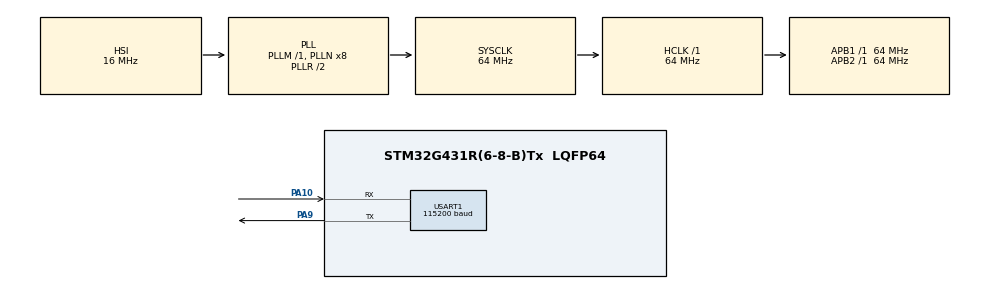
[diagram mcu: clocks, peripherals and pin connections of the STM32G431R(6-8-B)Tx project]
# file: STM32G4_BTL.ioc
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CRC.InputDataFormat=CRC_INPUTDATA_FORMAT_WORDS
Mcu.Family=STM32G4
Mcu.Name=STM32G431R(6-8-B)Tx
Mcu.Package=LQFP64
NVIC.PriorityGroup=NVIC_PRIORITYGROUP_4
PA10.Mode=Asynchronous
PA10.Signal=USART1_RX
PA9.Mode=Asynchronous
PA9.Signal=USART1_TX
ProjectManager.HeapSize=0x200
ProjectManager.StackSize=0x400
ProjectManager.TargetToolchain=STM32CubeIDE
RCC.ADC12Freq_Value=64000000
RCC.AHBFreq_Value=64000000
RCC.APB1Freq_Value=64000000
RCC.APB1TimFreq_Value=64000000
RCC.APB2Freq_Value=64000000
RCC.APB2TimFreq_Value=64000000
RCC.CortexFreq_Value=64000000
RCC.EXTERNAL_CLOCK_VALUE=12288000
RCC.HCLKFreq_Value=64000000
RCC.HSE_VALUE=8000000
RCC.HSI48_VALUE=48000000
RCC.HSI_VALUE=16000000
RCC.LSE_VALUE=32768
RCC.SYSCLKFreq_VALUE=64000000
RCC.SYSCLKSource=RCC_SYSCLKSOURCE_PLLCLK
RCC.USBFreq_Value=64000000
RCC.VCOOutputFreq_Value=128000000
USART1.BaudRate=115200
USART1.VirtualMode-Asynchronous=VM_ASYNC
VP_CRC_VS_CRC.Mode=CRC_Activate
VP_SYS_VS_DBSignals.Mode=DisableDeadBatterySignals
board=custom

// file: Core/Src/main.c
/* USER CODE BEGIN Header */
/**
  ******************************************************************************
  * @file           : main.c
  * @brief          : Main program body
  ******************************************************************************
  * @attention
  *
  * Copyright (c) 2026 STMicroelectronics.
  * All rights reserved.
  *
  * This software is licensed under terms that can be found in the LICENSE file
  * in the root directory of this software component.
  * If no LICENSE file comes with this software, it is provided AS-IS.
  *
  ******************************************************************************
  */
/* USER CODE END Header */
#include "main.h"

CRC_HandleTypeDef hcrc;

UART_HandleTypeDef huart1;

void SystemClock_Config(void);
static void MX_GPIO_Init(void);
static void MX_USART1_UART_Init(void);
static void MX_CRC_Init(void);

/* USER CODE BEGIN 0 */
typedef void (*pFunction)(void);

#define APP_ADDRESS			0x08008000U
/* USER CODE END 0 */

int main(void)
{

  /* USER CODE BEGIN 1 */
//	SCB->VTOR = 0x8006000;
//			__set_PRIMASK(0);
  /* USER CODE END 1 */

  /* MCU Configuration--------------------------------------------------------*/

  /* Reset of all peripherals, Initializes the Flash interface and the Systick. */
  HAL_Init();

  /* Configure the system clock */
  SystemClock_Config();

  /* Initialize all configured peripherals */
  MX_GPIO_Init();
  MX_USART1_UART_Init();
  MX_CRC_Init();
  /* USER CODE BEGIN 2 */

  HAL_UART_Transmit(&huart1, "rsB\n", 4, 1000);
  /* USER CODE END 2 */

  /* Infinite loop */
  /* USER CODE BEGIN WHILE */
  while (1)
  {
	  init();
    /* USER CODE END WHILE */

  }
}

void SystemClock_Config(void)
{
  RCC_OscInitTypeDef RCC_OscInitStruct = {0};
  RCC_ClkInitTypeDef RCC_ClkInitStruct = {0};

  /** Configure the main internal regulator output voltage
  */
  HAL_PWREx_ControlVoltageScaling(PWR_REGULATOR_VOLTAGE_SCALE1);

  /** Initializes the RCC Oscillators according to the specified parameters
  * in the RCC_OscInitTypeDef structure.
  */
  RCC_OscInitStruct.OscillatorType = RCC_OSCILLATORTYPE_HSI;
  RCC_OscInitStruct.HSIState = RCC_HSI_ON;
  RCC_OscInitStruct.HSICalibrationValue = RCC_HSICALIBRATION_DEFAULT;
  RCC_OscInitStruct.PLL.PLLState = RCC_PLL_ON;
  RCC_OscInitStruct.PLL.PLLSource = RCC_PLLSOURCE_HSI;
  RCC_OscInitStruct.PLL.PLLM = RCC_PLLM_DIV1;
  RCC_OscInitStruct.PLL.PLLN = 8;
  RCC_OscInitStruct.PLL.PLLP = RCC_PLLP_DIV2;
  RCC_OscInitStruct.PLL.PLLQ = RCC_PLLQ_DIV2;
  RCC_OscInitStruct.PLL.PLLR = RCC_PLLR_DIV2;
  if (HAL_RCC_OscConfig(&RCC_OscInitStruct) != HAL_OK)
  {
    Error_Handler();
  }

  /** Initializes the CPU, AHB and APB buses clocks
  */
  RCC_ClkInitStruct.ClockType = RCC_CLOCKTYPE_HCLK|RCC_CLOCKTYPE_SYSCLK
                              |RCC_CLOCKTYPE_PCLK1|RCC_CLOCKTYPE_PCLK2;
  RCC_ClkInitStruct.SYSCLKSource = RCC_SYSCLKSOURCE_PLLCLK;
  RCC_ClkInitStruct.AHBCLKDivider = RCC_SYSCLK_DIV1;
  RCC_ClkInitStruct.APB1CLKDivider = RCC_HCLK_DIV1;
  RCC_ClkInitStruct.APB2CLKDivider = RCC_HCLK_DIV1;

  if (HAL_RCC_ClockConfig(&RCC_ClkInitStruct, FLASH_LATENCY_2) != HAL_OK)
  {
    Error_Handler();
  }
}

static void MX_CRC_Init(void)
{

  hcrc.Instance = CRC;
  hcrc.Init.DefaultPolynomialUse = DEFAULT_POLYNOMIAL_ENABLE;
  hcrc.Init.DefaultInitValueUse = DEFAULT_INIT_VALUE_ENABLE;
  hcrc.Init.InputDataInversionMode = CRC_INPUTDATA_INVERSION_NONE;
  hcrc.Init.OutputDataInversionMode = CRC_OUTPUTDATA_INVERSION_DISABLE;
  hcrc.InputDataFormat = CRC_INPUTDATA_FORMAT_WORDS;
  if (HAL_CRC_Init(&hcrc) != HAL_OK)
  {
    Error_Handler();
  }

}

static void MX_USART1_UART_Init(void)
{

  huart1.Instance = USART1;
  huart1.Init.BaudRate = 115200;
  huart1.Init.WordLength = UART_WORDLENGTH_8B;
  huart1.Init.StopBits = UART_STOPBITS_1;
  huart1.Init.Parity = UART_PARITY_NONE;
  huart1.Init.Mode = UART_MODE_TX_RX;
  huart1.Init.HwFlowCtl = UART_HWCONTROL_NONE;
  huart1.Init.OverSampling = UART_OVERSAMPLING_16;
  huart1.Init.OneBitSampling = UART_ONE_BIT_SAMPLE_DISABLE;
  huart1.Init.ClockPrescaler = UART_PRESCALER_DIV1;
  huart1.AdvancedInit.AdvFeatureInit = UART_ADVFEATURE_NO_INIT;
  if (HAL_UART_Init(&huart1) != HAL_OK)
  {
    Error_Handler();
  }
  if (HAL_UARTEx_SetTxFifoThreshold(&huart1, UART_TXFIFO_THRESHOLD_1_8) != HAL_OK)
  {
    Error_Handler();
  }
  if (HAL_UARTEx_SetRxFifoThreshold(&huart1, UART_RXFIFO_THRESHOLD_1_8) != HAL_OK)
  {
    Error_Handler();
  }
  if (HAL_UARTEx_DisableFifoMode(&huart1) != HAL_OK)
  {
    Error_Handler();
  }

}

static void MX_GPIO_Init(void)
{

  /* GPIO Ports Clock Enable */
  __HAL_RCC_GPIOA_CLK_ENABLE();

}

void Error_Handler(void)
{
  __disable_irq();
  while (1)
  {
  }
}
